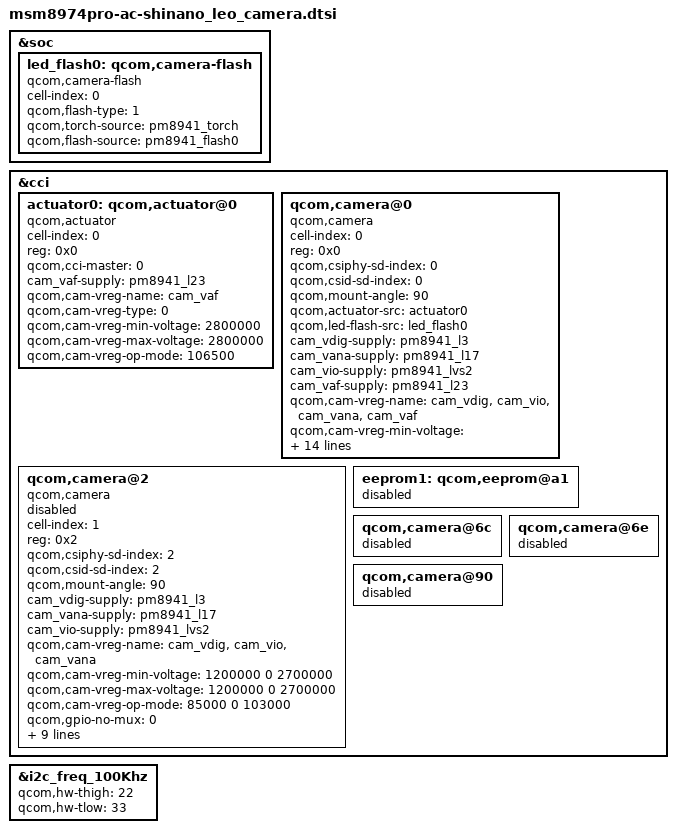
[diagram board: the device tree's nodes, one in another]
/* arch/arm/boot/dts/msm8974pro-ac-shinano_leo_camera.dtsi
 *
 * Copyright (C) 2014 Sony Mobile Communications Inc.
 *
 * This program is free software; you can redistribute it and/or modify
 * it under the terms of the GNU General Public License version 2 and
 * only version 2 as published by the Free Software Foundation.
 *
 * This program is distributed in the hope that it will be useful,
 * but WITHOUT ANY WARRANTY; without even the implied warranty of
 * MERCHANTABILITY or FITNESS FOR A PARTICULAR PURPOSE.  See the
 * GNU General Public License for more details.
 *
 *
 * NOTE: This file has been modified by Sony Mobile Communications Inc.
 * Modifications are licensed under the License.
 */

&soc {
        led_flash0: qcom,camera-flash {
                cell-index = <0>;
                compatible = "qcom,camera-flash";
                qcom,flash-type = <1>;
		qcom,torch-source = <&pm8941_torch>;
                qcom,flash-source = <&pm8941_flash0>;
        };
};

&cci {
	actuator0: qcom,actuator@0 {
		cell-index = <0>;
		reg = <0x0>;
		compatible = "qcom,actuator";
		qcom,cci-master = <0>;
		cam_vaf-supply = <&pm8941_l23>;
		qcom,cam-vreg-name = "cam_vaf";
		qcom,cam-vreg-type = <0>;
		qcom,cam-vreg-min-voltage = <2800000>;
		qcom,cam-vreg-max-voltage = <2800000>;
		qcom,cam-vreg-op-mode = <106500>;
	};

	qcom,camera@0 {
		cell-index = <0>;
		compatible = "qcom,camera";
		reg = <0x0>;
		qcom,csiphy-sd-index = <0>;
		qcom,csid-sd-index = <0>;
		qcom,mount-angle = <90>;
		qcom,actuator-src = <&actuator0>;
		qcom,led-flash-src = <&led_flash0>;
		cam_vdig-supply = <&pm8941_l3>;
		cam_vana-supply = <&pm8941_l17>;
		cam_vio-supply = <&pm8941_lvs2>;
		cam_vaf-supply = <&pm8941_l23>;
		qcom,cam-vreg-name = "cam_vdig", "cam_vio", "cam_vana", "cam_vaf";
		qcom,cam-vreg-min-voltage = <1200000 0 2700000 2800000>;
		qcom,cam-vreg-max-voltage = <1200000 0 2700000 2800000>;
		qcom,cam-vreg-op-mode = <105000 0 85600 106500>;
		qcom,gpio-no-mux = <0>;
		gpios = <&msmgpio 15 0>, <&msmgpio 94 0>;
		qcom,gpio-reset = <1>;
		qcom,gpio-req-tbl-num = <0 1>;
		qcom,gpio-req-tbl-flags = <1 0>;
		qcom,gpio-req-tbl-label = "CAMIF_MCLK0", "CAM_RESET0";
		qcom,sensor-position = <0>;
		qcom,sensor-mode = <0>;
		qcom,cci-master = <0>;
		status = "ok";
		clock-names = "cam_src_clk", "cam_clk";
	};

	qcom,camera@2 {
		cell-index = <1>;
		compatible = "qcom,camera";
		reg = <0x2>;
		qcom,csiphy-sd-index = <2>;
		qcom,csid-sd-index = <2>;
		qcom,mount-angle = <90>;
		cam_vdig-supply = <&pm8941_l3>;
		cam_vana-supply = <&pm8941_l17>;
		cam_vio-supply = <&pm8941_lvs2>;
		qcom,cam-vreg-name = "cam_vdig", "cam_vio", "cam_vana";
		qcom,cam-vreg-min-voltage = <1200000 0 2700000>;
		qcom,cam-vreg-max-voltage = <1200000 0 2700000>;
		qcom,cam-vreg-op-mode = <85000 0 103000>;
		qcom,gpio-no-mux = <0>;
		gpios = <&msmgpio 17 0>, <&msmgpio 18 0>;
		qcom,gpio-reset = <1>;
		qcom,gpio-req-tbl-num = <0 1>;
		qcom,gpio-req-tbl-flags = <1 0>;
		qcom,gpio-req-tbl-label = "CAMIF_MCLK2", "CAM_RESET1";
		qcom,sensor-position = <1>;
		qcom,sensor-mode = <1>;
		qcom,cci-master = <1>;
		clock-names = "cam_src_clk", "cam_clk";

		status="disable";
	};

	eeprom1: qcom,eeprom@a1 {
		status = "disabled";
	};

	qcom,camera@6c {
		status = "disabled";
	};

	/* disable Qualcomm camera sensors */
	qcom,camera@6e {
		status = "disabled";
	};

	qcom,camera@90 {
		status = "disabled";
	};

};

&i2c_freq_100Khz {
	qcom,hw-thigh = <22>;
	qcom,hw-tlow = <33>;
};
